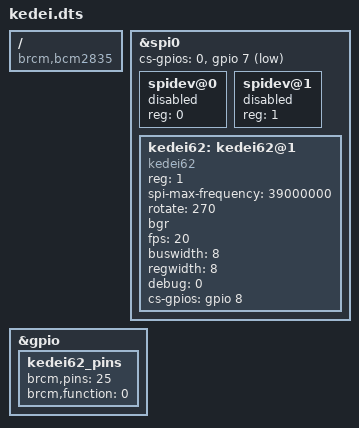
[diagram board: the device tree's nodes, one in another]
/dts-v1/;
/plugin/;

/ {
    compatible = "brcm,bcm2835", "brcm,bcm2837";

	fragment@0 {
		target = <&spi0>;
		__overlay__ {
			status = "okay";
			#address-cells = <1>;
			#size-cells = <0>;

			/*
			 * Override cs-gpios:
			 *   CE0 slot: <0> = not managed by SPI core (GPIO 8
			 *     is used by the kedei62 driver as a 74HC595 latch
			 *     signal, so we must keep it free here).
			 *   CE1 slot: GPIO 7, active-low — the KeDei CPLD
			 *     accepts data while CE1 is held LOW.
			 */
			cs-gpios = <0>,              /* CE0: not managed  */
				   <&gpio 7 1>;      /* CE1: GPIO_ACTIVE_LOW */

			spidev@0{
				reg = <0>;
				status = "disabled";
			};

			spidev@1{
				reg = <1>;
				status = "disabled";
			};
		};
	};

    fragment@1 {
		target = <&gpio>;
		__overlay__ {
			kedei62_pins: kedei62_pins {
				brcm,pins = <25>;
				brcm,function = <0>; /* in */
			};
		};
	};

	fragment@2 {
		target = <&spi0>;
		__overlay__ {
			/* needed to avoid dtc warning */
			#address-cells = <1>;
			#size-cells = <0>;

			kedei62: kedei62@1{
				compatible = "kedei62";
				reg = <1>;

				spi-max-frequency = <39000000>;
				rotate = <270>;
				bgr;
				fps = <20>;
				buswidth = <8>;
				regwidth = <8>;
				debug = <0>;

				/*
				 * The KeDei board routes GPIO 8 (CE0)
				 * to the 74HC595 RCLK (latch) input.
				 * fbtft reads this as par->gpio.cs and
				 * kedei_write() toggles it around every
				 * 3-byte SPI packet.
				 */
				cs-gpios = <&gpio 8 0>; /* GPIO_ACTIVE_HIGH */
			};

			/*
			 * Touchscreen disabled while GPIO 8 is used
			 * as the display latch signal.  Re-enable once
			 * a GPIO-sharing solution is in place.
			 *
			 * kedei62-ts@0 {
			 *	compatible = "ti,ads7846";
			 *	reg = <0>;
			 *
			 *	spi-max-frequency = <2000000>;
			 *	interrupts = <25 2>;
			 *	interrupt-parent = <&gpio>;
			 *	pendown-gpio = <&gpio 25 0>;
			 *	ti,x-plate-ohms = /bits/ 16 <60>;
			 *	ti,pressure-max = /bits/ 16 <255>;
			 * };
			 */

		};
	};
	__overrides__ {
		speed =		<&kedei62>,"spi-max-frequency:0";
		rotate =	<&kedei62>,"rotate:0";
		fps =		<&kedei62>,"fps:0";
		debug =		<&kedei62>,"debug:0";
	};

};
